# SYNCBOX_CALC3_ICONT register map
Vendor: Texas Instruments
Peripheral module from a debugger description file (folder omap5430_ES2_PUBLIC).
Registers are 32-bit, access per field, reset 0x0 unless marked. A register's access mark holds for its fields unless they carry their own. Offsets are as the file gives them; lines under a group give offsets from that group; [hi:lo] are bit positions; {n}, {i} and the like mark numbered series; 'fields as' and 'values as' point back to an identical list; <NAME> marks a mode.

## SYNCBOX_CALC3_ICONT
0x00 SYNCBOX_REVISION ro reset not defined — IP revision identifier
  [31:0] REVISION — IP revision
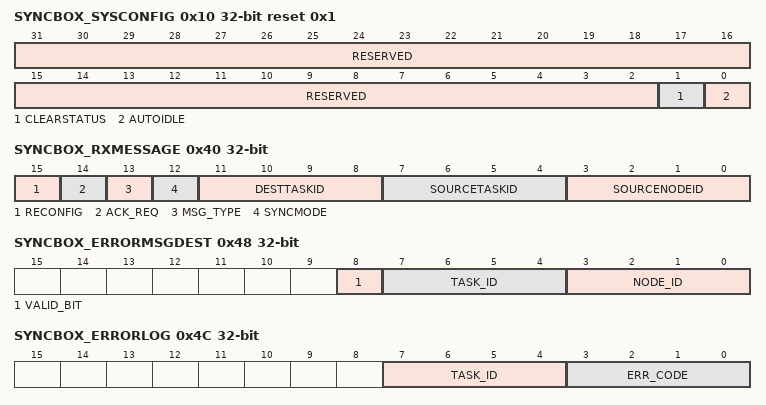
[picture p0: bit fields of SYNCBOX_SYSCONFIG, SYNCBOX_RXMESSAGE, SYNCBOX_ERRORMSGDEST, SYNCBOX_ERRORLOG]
0x10 SYNCBOX_SYSCONFIG reset 0x1 — This register allows controlling various parameters of the OCP interface.
  [31:2] RESERVED ro — Read returns 0.
  [1] CLEARSTATUS rw — Set to 1 to clear dynamic registers
    0=Clear_status_done,_no_pending_action; 0=No_action; 1=Initiate_Clear_status; 1=Clear_status_ongoing
  [0] AUTOIDLE rw — Internal OCP clock gating strategy:
    0=OCP_clock_is_free-running; 1=OCP_OCP_1 (Automatic OCP clock-gating strategy is applied based on the OCP interface activity.)
0x40 SYNCBOX_RXMESSAGE — Register containing the received message, from the CTL_IN interface or MSG_IN interface
  [15] RECONFIG wo — Bit to allow dynamic reconfiguration – not used
  [14] ACK_REQ wo — Bit set to 1 in input message if an acknowledge message must be returned.
  [13] MSG_TYPE wo — Message type 0: Acknowledge message 1: Activation message
  [12] SYNCMODE wo — Synchronous message type: 0 Synchronous 1: Asynchronous
  [11:8] DESTTASKID wo — Task identifier of the destination node
  [7:4] SOURCETASKID wo — Task identifier of the message sender
  [3:0] SOURCENODEID wo — Node identifier of the message sender
0x44 SYNCBOX_NODEIDENTIFIER ro reset not defined — Contains the node identifier. Initialized by default to the tie-off value.
  [3:0] VALUE — Node identifier value
0x48 SYNCBOX_ERRORMSGDEST — Register containing the node and task identifier to send an activation message when an error is detected
  [8] VALID_BIT rw — Validity bit use to send or not the error message to a CPU based node
  [7:4] TASK_ID rw — Identifier for the task in charge of recovering error
  [3:0] NODE_ID rw — Identifier for the node in charge of recovering error
0x4C SYNCBOX_ERRORLOG — Contains the different errors latched during message decoding. Any write to the register resets the current value.
  [7:4] TASK_ID rw — Identifier of the task (or event line) to which error is attached.
  [3:0] ERR_CODE rw — 4 bits coding the error code
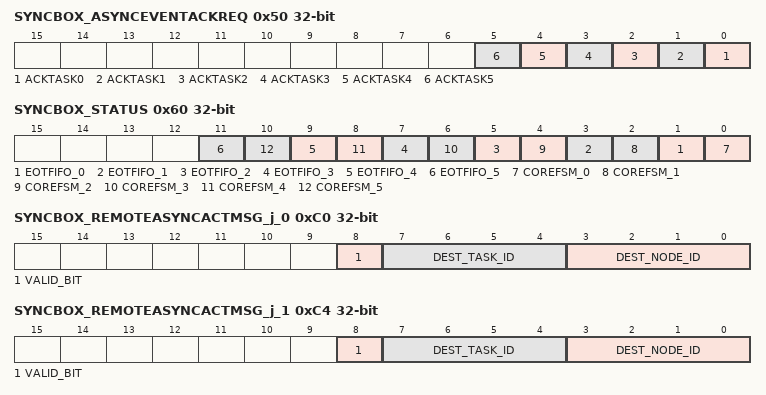
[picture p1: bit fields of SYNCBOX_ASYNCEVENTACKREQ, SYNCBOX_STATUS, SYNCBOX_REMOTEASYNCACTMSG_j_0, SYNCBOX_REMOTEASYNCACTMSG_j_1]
0x50 SYNCBOX_ASYNCEVENTACKREQ — Each bit in this register defines whether the corresponding asynchronous line event need an acknowledge upon task completion or directly when the line is raised.
  [all] fields
    0=No acknowledge message expected on this line; 1=Acknowledge message expected on this line
  [n] ACKTASK{n} rw (n=0..5)
0x54 SYNCBOX_PARAMADDR_MOD — Modulo value for the configuration parameter pointer computed by SYNCBOX
  [7:0] VALUE rw — Number of macroblock configuration arrays in pipeline
0x60 SYNCBOX_STATUS ro
  [2n+1] EOTFIFO_{n} (n=0..5) — EndOfTask FIFO empty (0) or not empty (1)
  [2n] COREFSM_{n} (n=0..5) — Status bit for task {n}
0xC0 SYNCBOX_REMOTEASYNCACTMSG_j_0 — Contains the task and node identifier to send the activation message to, upon detection of an asynchronous event
  [8] VALID_BIT rw — Validity bit of current register content: If set to 0, the two fields dest_node_id and dest_task_id can be ignored; if set to 1, the two fields dest_node_id and dest_task_id are used to send activation message.
  [7:4] DEST_TASK_ID rw — Destination task identifier telling at which task in the destination node the activation message must be sent upon task completion
  [3:0] DEST_NODE_ID rw — Destination node identifier
0xC4 SYNCBOX_REMOTEASYNCACTMSG_j_1 — Contains the task and node identifier to send the activation message to, upon detection of an asynchronous event
  fields as SYNCBOX_REMOTEASYNCACTMSG_j_0
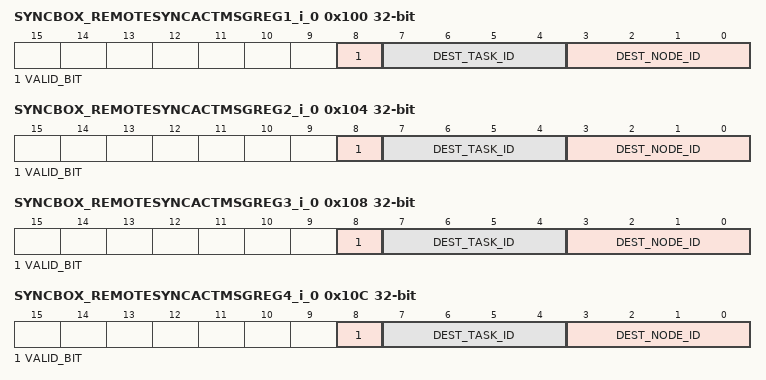
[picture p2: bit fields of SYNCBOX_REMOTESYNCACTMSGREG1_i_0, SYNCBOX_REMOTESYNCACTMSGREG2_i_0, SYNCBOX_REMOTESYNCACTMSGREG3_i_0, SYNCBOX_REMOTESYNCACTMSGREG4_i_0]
0x100 SYNCBOX_REMOTESYNCACTMSGREG1_i_0 — Contains destination task identifier and destination node identifier for activation messages to be sent upon task completion. Valid bit is used to loop on all registers of the bundle.
  fields as SYNCBOX_REMOTEASYNCACTMSG_j_0
0x104 SYNCBOX_REMOTESYNCACTMSGREG2_i_0 — Contains destination task identifier and destination node identifier for activation messages to be sent upon task completion. Valid bit is used to loop on all registers of the bundle.
  [8] VALID_BIT rw — Validity bit of current register content: If set to 0, the two fields dest_node_id and dest_task_id can be ignored; if f set to 1, the two fields dest_node_id and dest_task_id are used to send activation message.
  [7:4] DEST_TASK_ID rw — Destination task identifier telling at which task in the destination node the activation message must be sent upon task completion
  [3:0] DEST_NODE_ID rw — Destination node identifier
0x108 SYNCBOX_REMOTESYNCACTMSGREG3_i_0 — Contains destination task identifier and destination node identifier for activation messages to be sent upon task completion. Valid bit is used to loop on all registers of the bundle.
  [8] VALID_BIT rw — Validity bit of current register content: If set to 0, the two fields dest_node_id and dest_task_id can be ignored; if set to 1, the two fields dest_node_id and dest_task_id are used to send activation message
  [7:4] DEST_TASK_ID rw — Destination task identifier telling at which task in destination node the activation message must be sent upon task completion
  [3:0] DEST_NODE_ID rw — Destination node identifier
0x10C SYNCBOX_REMOTESYNCACTMSGREG4_i_0 — Contains destination task identifier and destination node identifier for activation messages to be sent upon task completion. Valid bit is used to loop on all registers of the bundle
  fields as SYNCBOX_REMOTEASYNCACTMSG_j_0
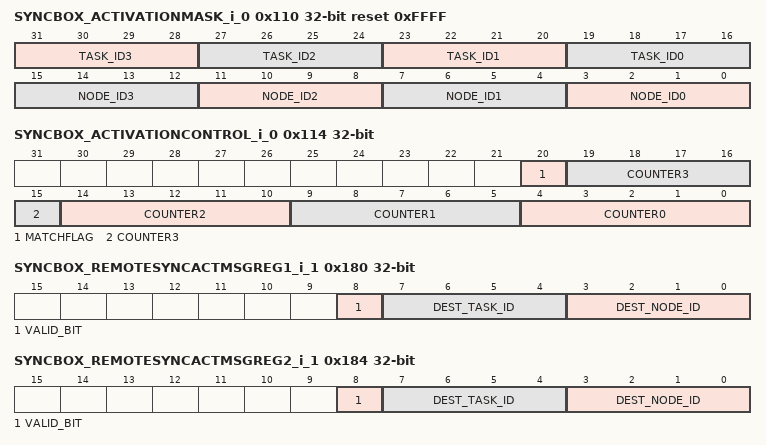
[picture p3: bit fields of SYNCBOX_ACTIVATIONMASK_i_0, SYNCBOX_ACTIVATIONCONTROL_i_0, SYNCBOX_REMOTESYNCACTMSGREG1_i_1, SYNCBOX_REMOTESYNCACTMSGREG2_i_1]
0x110 SYNCBOX_ACTIVATIONMASK_i_0 rw reset 0xFFFF — Applies for synchronous task description of bit fields given below. For asynchronous task, only the 16 LSBs are used. Each of the 16 LSBs corresponds to a 1 hot encoding value for the node identifier. 16 MSBs write access is protected by the corresponding bit in the register.
  [31:28] TASK_ID3 — For synchronous message: Each quad bit contains the task ID of a potential activator for asynchronous message. This quad bit contains the task ID to which the ack message must be sent at end of processing.
  [27:24] TASK_ID2 — For synchronous message: Each quad bit contains the task ID of a potential activator for asynchronous message. This quad bit contains the node ID to which the ack message must be sent at end of processing.
  [23:20] TASK_ID1 — For synchronous message: Each quad bit contains the task ID of a potential activator for asynchronous message. This quad bit contains the task ID to which the ack message must be sent at end of processing.
  [19:16] TASK_ID0 — For synchronous message: Each quad bit contains the task ID of a potential activator for asynchronous message. This quad bit contains the node ID to which the ack message must be sent at end of processing.
  [4n+3:4n] NODE_ID{n} (n=0..3) — For synchronous message: Each quad bit contains the node ID of a potential activator for asynchronous message. Bit i set to 1 means an activation message is awaited from node i.
0x114 SYNCBOX_ACTIVATIONCONTROL_i_0 ro — Contains the four activation counters
  [20] MATCHFLAG — Bit set to 1 when all activation messages received
  [19:15] COUNTER3 — Associated counter with the fourth activator
  [14:10] COUNTER2 — Associated counter with the third activator
  [9:5] COUNTER1 — Associated counter with the second activator
  [4:0] COUNTER0 — Associated counter with the first activator
0x118 SYNCBOX_NEWTASKCOUNTER_i_0 ro — NewTask counter
  [12:0] VALUE — Counter of the number of times the NewTask signal has been activated. This is not a macroblock counter because N MB can be processed every call.
0x120 SYNCBOX_PARAMADDR_BASE_i_0 — Base address for the node configuration parameters
  [15:0] VALUE rw — 128-bit address
0x124 SYNCBOX_PARAMADDR_INC_i_0 — Contains the parameter address increment to be added to the current parameter address pointer
  [15:0] VALUE rw — Value of the increment
0x128 SYNCBOX_PARAMADDR_IF_i_0 ro reset not defined — Interface register containing the current value of the MB configuration parameters. This register is read by the node core.
  [15:0] VALUE — 16-bit value containing a 128-bit pointer
0x180 SYNCBOX_REMOTESYNCACTMSGREG1_i_1 — Contains destination task identifier and destination node identifier for activation messages to be sent upon task completion. Valid bit is used to loop on all registers of the bundle.
  fields as SYNCBOX_REMOTEASYNCACTMSG_j_0
0x184 SYNCBOX_REMOTESYNCACTMSGREG2_i_1 — Contains destination task identifier and destination node identifier for activation messages to be sent upon task completion. Valid bit is used to loop on all registers of the bundle.
  fields as SYNCBOX_REMOTESYNCACTMSGREG2_i_0
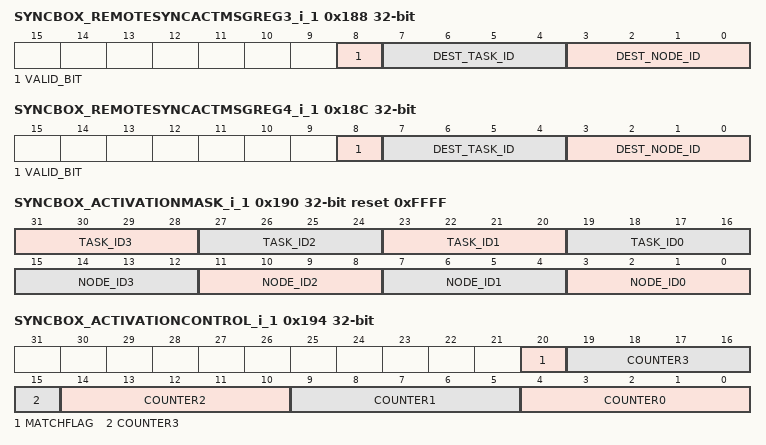
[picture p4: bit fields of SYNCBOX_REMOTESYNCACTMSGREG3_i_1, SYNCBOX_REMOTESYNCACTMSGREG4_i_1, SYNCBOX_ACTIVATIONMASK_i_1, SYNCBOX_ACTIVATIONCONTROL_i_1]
0x188 SYNCBOX_REMOTESYNCACTMSGREG3_i_1 — Contains destination task identifier and destination node identifier for activation messages to be sent upon task completion. Valid bit is used to loop on all registers of the bundle.
  fields as SYNCBOX_REMOTESYNCACTMSGREG3_i_0
0x18C SYNCBOX_REMOTESYNCACTMSGREG4_i_1 — Contains destination task identifier and destination node identifier for activation messages to be sent upon task completion. Valid bit is used to loop on all registers of the bundle
  fields as SYNCBOX_REMOTEASYNCACTMSG_j_0
0x190 SYNCBOX_ACTIVATIONMASK_i_1 rw reset 0xFFFF — Applies for synchronous task description of bit fields given below. For asynchronous task, only the 16 LSBs are used. Each of the 16 LSBs corresponds to a 1 hot encoding value for the node identifier. 16 MSBs write access is protected by the corresponding bit in the register.
  fields as SYNCBOX_ACTIVATIONMASK_i_0
0x194 SYNCBOX_ACTIVATIONCONTROL_i_1 ro — Contains the four activation counters
  fields as SYNCBOX_ACTIVATIONCONTROL_i_0
0x198 SYNCBOX_NEWTASKCOUNTER_i_1 ro — NewTask counter
  fields as SYNCBOX_NEWTASKCOUNTER_i_0
0x1A0 SYNCBOX_PARAMADDR_BASE_i_1 — Base address for the node configuration parameters
  [15:0] VALUE rw — 128-bit address
0x1A4 SYNCBOX_PARAMADDR_INC_i_1 — Contains the parameter address increment to be added to the current parameter address pointer
  [15:0] VALUE rw — Value of the increment
0x1A8 SYNCBOX_PARAMADDR_IF_i_1 ro reset not defined — Interface register containing the current value of the MB configuration parameters. This register is read by the node core.
  [15:0] VALUE — 16-bit value containing a 128-bit pointer
